# RE01_256KB register map
Vendor: Renesas Electronics Corporation; Series: RE01; File version: 1.00.01
CPU: CM0PLUS r0p1, little endian, MPU, no FPU, VTOR, 2 interrupt priority bits, 32 interrupts
Registers are 8-bit, read-write, reset 0x0 unless marked. A register's access mark holds for its fields unless they carry their own. Offsets are from the block's base; [hi:lo] are bit positions; {n}, {i} and the like mark numbered series.

## CRC — Cyclic Redundancy Check Calculator
Base 0x40074000
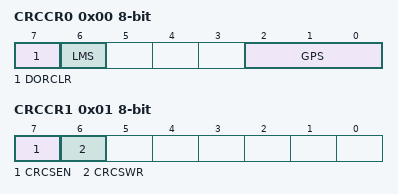
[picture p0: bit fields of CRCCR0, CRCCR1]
0x00 CRCCR0 — CRC Control Register 0
  [7] DORCLR wo — CRCDOR/CRCDOR_HA/CRCDOR_BY Register Clear
    0=No effect; 1=Clear the CRCDOR/CRCDOR_HA/CRCDOR_BY register
  [6] LMS — CRC Calculation Switching
    0=Generate CRC code for LSB-first communication; 1=Generate CRC code for MSB-first communication
  [2:0] GPS — CRC Generating Polynomial Switching
    1=8-bit CRC-8 (X8 + X2 + X + 1); 2=16-bit CRC-16 (X16 + X15 + X2 + 1); 3=16-bit CRC-CCITT (X16 + X12 + X5 + 1); 4=32-bit CRC-32 (X32 + X26 + X23 + X22 + X16 + X12 + X11 +X10 + X8 + X7 + X5 + X4 + X2 + X + 1); 5=32-bit CRC-32C (X32 + X28 + X27 + X26 + X25 + X23 + X22 + X20 + X19 + X18 + X14 + X13 + X11 + X10 + X9 + X8 + X6 + 1); other=Others (No calculation is executed)
0x01 CRCCR1 — CRC Control Register 1
  [7] CRCSEN — Snoop Enable
    0=Disabled; 1=Enabled
  [6] CRCSWR — Snoop-On-Write/Read Switch
    0=Snoop-on-read; 1=Snoop-on-write
0x04 CRCDIR 32-bit — CRC Data Input Register
0x04 CRCDIR_BY (alternate view of CRCDIR) — CRC Data Input Register
0x08 CRCDOR 32-bit — CRC Data Output Register
0x08 CRCDOR_HA 16-bit (alternate view of CRCDOR) — CRC Data Output Register
0x08 CRCDOR_BY (alternate view of CRCDOR) — CRC Data Output Register
0x0C CRCSAR 16-bit — Snoop Address Register
  [13:0] CRCSA — Register Snoop Address

## KINT — Key Interrupt Function
Base 0x40080000
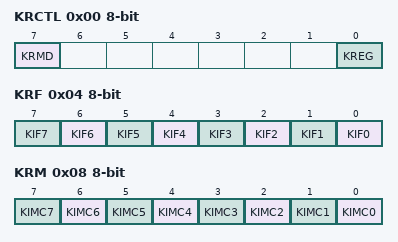
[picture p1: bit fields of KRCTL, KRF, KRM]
0x00 KRCTL — Key Return Control Register
  [7] KRMD — Usage of Key Interrupt Flags (KRF.KIF0 to KRF.KIF7)
    0=Do not use key interrupt flags; 1=Use key interrupt flags
  [0] KREG — Detection Edge Selection (KRM00 to KRM07 pins)
    0=Falling edge; 1=Rising edge
0x04 KRF — Key Return Flag Register
  [all] fields
    0=No interrupt detected; 1=Interrupt detected
  [n] KIF{n} (n=0..7) — Key Interrupt Flag n
0x08 KRM — Key Return Mode Register
  [all] fields
    0=Do not detect key interrupt signals; 1=Detect key interrupt signals
  [n] KIMC{n} (n=0..7) — Key Interrupt Mode Control n

## CCC — Clock Correction Circuit
Base 0x40080400
0x00 ADJUSTR 32-bit — Adjustment Register
  [8:0] ADJUST — Adjustment
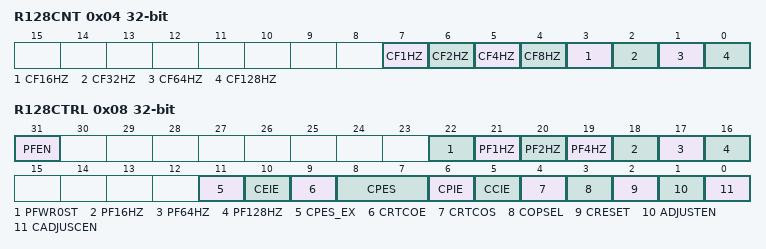
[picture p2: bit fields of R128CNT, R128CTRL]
0x04 R128CNT 32-bit ro — 128-Hz Counter
  [7] CF1HZ, [6] CF2HZ, [5] CF4HZ, [4] CF8HZ, [3] CF16HZ, [2] CF32HZ, [1] CF64HZ, [0] CF128HZ
0x08 R128CTRL 32-bit — 128-Hz Counter Control Register
  [31] PFEN — Periodic Interrupt Enable
    0=Periodic interrupt is disabled; 1=Periodic interrupt is enabled
  [22] PFWR0ST ro — Periodic Interrupt Status Flag
    0=The flag has been cleared; 1=The flag is being cleared
  [21] PF1HZ — 1-Second Periodic Interrupt Flag
    0=A 1-second periodic interrupt has not been generated; 1=A 1-second periodic interrupt has been generated
  [20] PF2HZ — 1/2-Second Periodic Interrupt Flag
    0=A 1/2-second periodic interrupt has not been generated; 1=A 1/2-second periodic interrupt has been generated
  [19] PF4HZ — 1/4-Second Periodic Interrupt Flag
    0=A 1/4-second periodic interrupt has not been generated; 1=A 1/4-second periodic interrupt has been generated
  [18] PF16HZ — 1/16-Second Periodic Interrupt Flag
    0=A 1/16-second periodic interrupt has not been generated; 1=A 1/16-second periodic interrupt has been generated
  [17] PF64HZ — 1/64-Second Periodic Interrupt Flag
    0=A 1/64-second periodic interrupt has not been generated; 1=A 1/64-second periodic interrupt has been generated
  [16] PF128HZ — 1/128-Second Periodic Interrupt Flag
    0=A 1/128-second periodic interrupt has not beengenerated; 1=A 1/128-second periodic interrupt has been generated
  [11] CPES_EX — Periodic Interrupt Select
  [10] CEIE — Read Error Interrupt Enable
    0=Disable read error interrupt request; 1=Enable read error interrupt request
  [9] CRTCOE — CCCOUT Output Enable
    0=Disable CCCOUT output; 1=Enable CCCOUT output
  [8:7] CPES — Periodic Interrupt Select
  [6] CPIE — Periodic Interrupt Enable
    0=Disable periodic interrupt request; 1=Enable periodic interrupt request
  [5] CCIE — Overflow Interrupt Enable
    0=Disable overflow interrupt request; 1=Enable overflow interrupt request
  [4] CRTCOS — CCCOUT Output Select
    0=1 Hz; 1=512 Hz
  [3] COPSEL — CCCOUT Output Port Select
    0=Output is from CCCOUT_A; 1=Output is from CCCOUT_B
  [2] CRESET — Software Reset
    0=No effect; 1=Initialize the CCC and the 128-Hz counter
  [1] ADJUSTEN — Frequency Correction Enable
    0=Disable CCC; 1=Enable CCC
  [0] CADJUSCEN — CCC Enable
    0=Stop; 1=Operate
